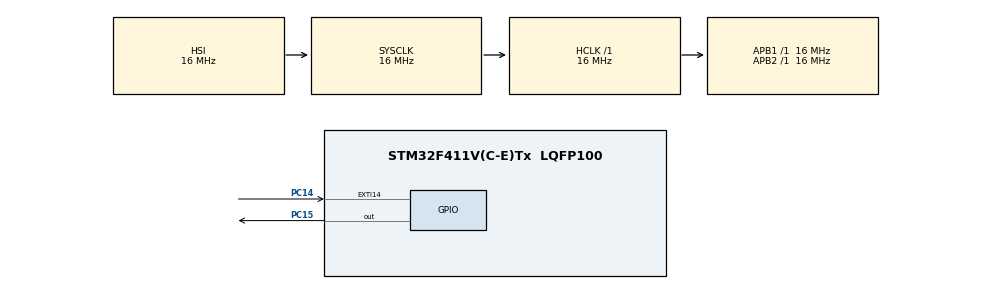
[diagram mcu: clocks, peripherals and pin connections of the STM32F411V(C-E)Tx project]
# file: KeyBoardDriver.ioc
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Mcu.Family=STM32F4
Mcu.Name=STM32F411V(C-E)Tx
Mcu.Package=LQFP100
NVIC.EXTI15_10_IRQn=true\:0\:0\:false\:false\:true\:true
NVIC.PriorityGroup=NVIC_PRIORITYGROUP_4
PC14-OSC32_IN.GPIO_ModeDefaultEXTI=GPIO_MODE_IT_FALLING
PC14-OSC32_IN.GPIO_PuPd=GPIO_NOPULL
PC14-OSC32_IN.Signal=GPXTI14
PC15-OSC32_OUT.GPIO_ModeDefaultOutputPP=GPIO_MODE_OUTPUT_OD
PC15-OSC32_OUT.Signal=GPIO_Output
PH0\ -\ OSC_IN.Mode=HSE-External-Oscillator
PH0\ -\ OSC_IN.Signal=RCC_OSC_IN
PH1\ -\ OSC_OUT.Mode=HSE-External-Oscillator
PH1\ -\ OSC_OUT.Signal=RCC_OSC_OUT
ProjectManager.HeapSize=0x200
ProjectManager.StackSize=0x400
ProjectManager.TargetToolchain=SW4STM32
RCC.AHBFreq_Value=16000000
RCC.APB1Freq_Value=16000000
RCC.APB2Freq_Value=16000000
RCC.CortexFreq_Value=16000000
RCC.HSE_VALUE=25000000
RCC.HSI_VALUE=16000000
RCC.LSE_VALUE=32768
RCC.SYSCLKFreq_VALUE=16000000
RCC.VCOOutputFreq_Value=192000000
board=custom

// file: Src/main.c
/* USER CODE BEGIN Header */
/**
  ******************************************************************************
  * @file           : main.c
  * @brief          : Main program body
  ******************************************************************************
  ** This notice applies to any and all portions of this file
  * that are not between comment pairs USER CODE BEGIN and
  * USER CODE END. Other portions of this file, whether
  * inserted by the user or by software development tools
  * are owned by their respective copyright owners.
  *
  * COPYRIGHT(c) 2018 STMicroelectronics
  *
  * Redistribution and use in source and binary forms, with or without modification,
  * are permitted provided that the following conditions are met:
  *   1. Redistributions of source code must retain the above copyright notice,
  *      this list of conditions and the following disclaimer.
  *   2. Redistributions in binary form must reproduce the above copyright notice,
  *      this list of conditions and the following disclaimer in the documentation
  *      and/or other materials provided with the distribution.
  *   3. Neither the name of STMicroelectronics nor the names of its contributors
  *      may be used to endorse or promote products derived from this software
  *      without specific prior written permission.
  *
  * THIS SOFTWARE IS PROVIDED BY THE COPYRIGHT HOLDERS AND CONTRIBUTORS "AS IS"
  * AND ANY EXPRESS OR IMPLIED WARRANTIES, INCLUDING, BUT NOT LIMITED TO, THE
  * IMPLIED WARRANTIES OF MERCHANTABILITY AND FITNESS FOR A PARTICULAR PURPOSE ARE
  * DISCLAIMED. IN NO EVENT SHALL THE COPYRIGHT HOLDER OR CONTRIBUTORS BE LIABLE
  * FOR ANY DIRECT, INDIRECT, INCIDENTAL, SPECIAL, EXEMPLARY, OR CONSEQUENTIAL
  * DAMAGES (INCLUDING, BUT NOT LIMITED TO, PROCUREMENT OF SUBSTITUTE GOODS OR
  * SERVICES; LOSS OF USE, DATA, OR PROFITS; OR BUSINESS INTERRUPTION) HOWEVER
  * CAUSED AND ON ANY THEORY OF LIABILITY, WHETHER IN CONTRACT, STRICT LIABILITY,
  * OR TORT (INCLUDING NEGLIGENCE OR OTHERWISE) ARISING IN ANY WAY OUT OF THE USE
  * OF THIS SOFTWARE, EVEN IF ADVISED OF THE POSSIBILITY OF SUCH DAMAGE.
  *
  ******************************************************************************
  */
/* USER CODE END Header */

#include "main.h"
#include "gpio.h"

/* USER CODE BEGIN PD */
typedef enum state_t {
	INVALID,
	IDLE,
	DATA,
	PARITY,
	STOP,
	SEND_START,
	SEND_DATA,
	SEND_PARITY,
	SEND_STOP,
	SEND_ACK
} state_t;
/* USER CODE END PD */

/* USER CODE BEGIN PV */
volatile uint8_t ind;
volatile uint8_t data;
volatile uint8_t parity;
volatile uint8_t is_data = 0;
volatile state_t state = IDLE;
/* USER CODE END PV */

void SystemClock_Config(void);
/* USER CODE BEGIN PFP */
void HAL_GPIO_EXTI_Callback(uint16_t GPIO_Pin) {
	if(GPIO_Pin == GPIO_PIN_14) {
		int bit = HAL_GPIO_ReadPin(GPIOC, GPIO_PIN_15);
		switch(state) {
		case IDLE: {
			if(bit == 0) {
				data = 0;
				state = DATA;
				ind = 0;
				parity = 1;
			}
			break;
		}
		case DATA: {
			data |= bit << ind;
			if(bit)
				parity = !parity;
			++ind;
			if(ind == 8)
				state = PARITY;
			break;
		}
		case PARITY: {
			if(bit != parity) {
				state = INVALID;
			}
			state = STOP;
			break;
		}
		case STOP: {
			if(bit != 1) {
				state = INVALID;
			}
			state = IDLE;
			is_data = 1;
			break;
		}
		case INVALID: {
			sendByte(0xFE);
			break;
		}
		case SEND_DATA: {
			HAL_GPIO_WritePin(GPIOC, GPIO_PIN_15, ((data >> ind) & 1));
			if(((data >> ind) & 1))
				parity = !parity;
			++ind;
			if(ind == 8)
				state = SEND_PARITY;
			break;
		}
		case SEND_PARITY: {
			HAL_GPIO_WritePin(GPIOC, GPIO_PIN_15, !parity);
			state = SEND_STOP;
			break;
		}
		case SEND_STOP: {
			HAL_GPIO_WritePin(GPIOC, GPIO_PIN_15, GPIO_PIN_SET);
			state = SEND_ACK;
			break;
		}
		case SEND_ACK: {
			HAL_GPIO_WritePin(GPIOC, GPIO_PIN_14, GPIO_PIN_SET);
			HAL_GPIO_WritePin(GPIOC, GPIO_PIN_15, GPIO_PIN_SET);
			state = IDLE;
			break;
		}
		default: {}
		}
	}
}

void sendByte(uint8_t byte) {
	state = SEND_START;
	ind = 0;
	parity = 0;
	data = byte;

	HAL_GPIO_WritePin(GPIOC, GPIO_PIN_14, GPIO_PIN_RESET);
	HAL_Delay(1);
	HAL_GPIO_WritePin(GPIOC, GPIO_PIN_15, GPIO_PIN_RESET);

	state = SEND_DATA;
	HAL_GPIO_WritePin(GPIOC, GPIO_PIN_14, GPIO_PIN_SET);

}

void sendTwoBytes(uint8_t b1, uint8_t b2) {
	sendByte(b1);
	while(!is_data) {}
	is_data = 0;
	sendByte(b2);
	while(!is_data) {}
	is_data = 0;
}
/* USER CODE END PFP */

int main(void)
{

  /* MCU Configuration--------------------------------------------------------*/

  /* Reset of all peripherals, Initializes the Flash interface and the Systick. */
  HAL_Init();

  /* Configure the system clock */
  SystemClock_Config();

  /* Initialize all configured peripherals */
  MX_GPIO_Init();
  /* USER CODE BEGIN 2 */
  GPIOC->MODER 	|= GPIO_MODER_MODER14_0;
  GPIOC->OTYPER |= GPIO_OTYPER_OT14;

  HAL_GPIO_WritePin(GPIOC, GPIO_PIN_14, GPIO_PIN_SET);
  HAL_GPIO_WritePin(GPIOC, GPIO_PIN_15, GPIO_PIN_SET);

  sendTwoBytes(0xED, 0x7);
  /* USER CODE END 2 */
  /* Infinite loop */
  /* USER CODE BEGIN WHILE */
  while (1)
  {
	  if(is_data) {
		  printf("%#x\n", data);
		  is_data = 0;
	  }
    /* USER CODE END WHILE */

  }
}

void SystemClock_Config(void)
{
  RCC_OscInitTypeDef RCC_OscInitStruct = {0};
  RCC_ClkInitTypeDef RCC_ClkInitStruct = {0};

  /**Configure the main internal regulator output voltage
  */
  __HAL_RCC_PWR_CLK_ENABLE();
  __HAL_PWR_VOLTAGESCALING_CONFIG(PWR_REGULATOR_VOLTAGE_SCALE1);
  /**Initializes the CPU, AHB and APB busses clocks
  */
  RCC_OscInitStruct.OscillatorType = RCC_OSCILLATORTYPE_HSI;
  RCC_OscInitStruct.HSIState = RCC_HSI_ON;
  RCC_OscInitStruct.HSICalibrationValue = RCC_HSICALIBRATION_DEFAULT;
  RCC_OscInitStruct.PLL.PLLState = RCC_PLL_NONE;
  if (HAL_RCC_OscConfig(&RCC_OscInitStruct) != HAL_OK)
  {
    Error_Handler();
  }
  /**Initializes the CPU, AHB and APB busses clocks
  */
  RCC_ClkInitStruct.ClockType = RCC_CLOCKTYPE_HCLK|RCC_CLOCKTYPE_SYSCLK
                              |RCC_CLOCKTYPE_PCLK1|RCC_CLOCKTYPE_PCLK2;
  RCC_ClkInitStruct.SYSCLKSource = RCC_SYSCLKSOURCE_HSI;
  RCC_ClkInitStruct.AHBCLKDivider = RCC_SYSCLK_DIV1;
  RCC_ClkInitStruct.APB1CLKDivider = RCC_HCLK_DIV1;
  RCC_ClkInitStruct.APB2CLKDivider = RCC_HCLK_DIV1;

  if (HAL_RCC_ClockConfig(&RCC_ClkInitStruct, FLASH_LATENCY_0) != HAL_OK)
  {
    Error_Handler();
  }
}

void Error_Handler(void)
{
}

/************************ (C) COPYRIGHT STMicroelectronics *****END OF FILE****/
